# RL6678_IP_SVD register map
Vendor: Realtek
Registers are 32-bit, read-write, reset 0x0 unless marked. A register's access mark holds for its fields unless they carry their own. Offsets are from the block's base; [hi:lo] are bit positions; lines under a group give offsets from that group; {n}, {i} and the like mark numbered series; <NAME> marks a mode.

## DDRC_REG
Base 0x41100000
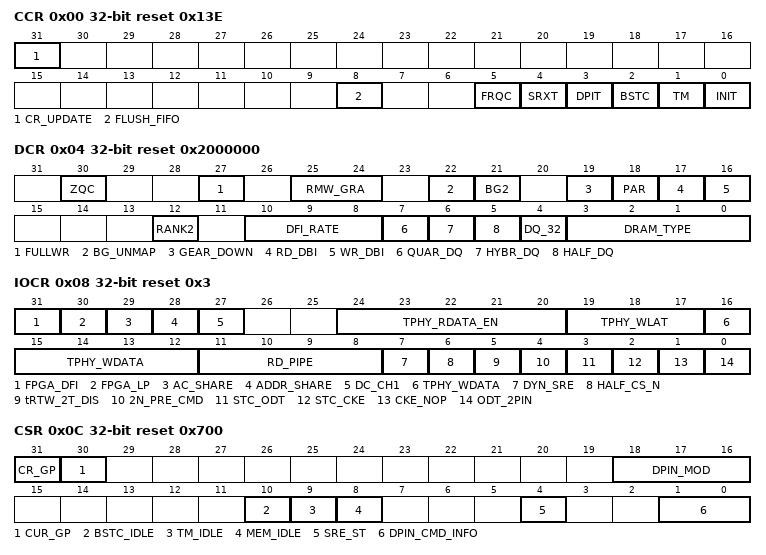
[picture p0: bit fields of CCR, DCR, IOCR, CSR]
0x00 CCR access per field reset 0x13E — Configuration Control Register
  [31] CR_UPDATE wo — To update the related control registers. Control registers: DCR, IOCR, CSR, MR_INFO,and MRx.To update the registers dynamically, it only allows until all transitions are complete. Timing counter registers: TPR0, TPR1, TPR2, and TPR3.
  [8] FLUSH_FIFO rw — Flush all FIFO in DRAMC. Write: 0: Not to flush FIFO 1: Start to Flush FIFO Read: 0: It is still active to flush FIFO. 1: Flushing FIFO operation is done.
  [5] FRQC rw — Set to implementation FRQC function. DRAMC would be automatically to implement serial operations and cooperate with RTK_PHY at the next Auto-refresh implementation finish. The operations include Self-refresh entry (SRE), to trigger RTK_PHY: Frequency change, wait until RTK_PHY: Frequency change done, set DRAM exit Self refresh mode (SRX) and re-initialize DRAM to set mode registers. The corresponding register group is according to CR_CSR.GP. Write: 0: Not to implement FRQC function. 1: Set FRQC function Read : 0: FRQC_function is still active. 1: FRQC function done. *Only support with configuration: FRQC_SUPPORT.
  [4] SRXT rw — Set to implementation SREX function. DRAMC would be automatically to implement DRAM: Self- Refresh entry command (SRE) at the next Auto-Refresh implementation finishing. And DRAMC would issue DRAM: Self-Refresh exit command (SRX) if Read/Write data access to DRAM. CR_CSR.SRE_ST is indicated DRAMC still implement SRE function. Write: 0: Not to set AUTO_SREX function. 1: Set AUTO_SREX function Read : 0: AUTO_SREX function is still active. 1: Indicates AUTO_SREX function done (SREX_DONE).
  [3] DPIT rw — Start to implement DPIN function. According to CR_CMD_DPIN//CR_CMD_DPIN_NDGE/CR_TIE_DPIN register value to set to DRAM pins. Write: 0: Not to set value to DRAM command pins. 1: Set value to DRAM pins. Read: 0: DPIN function is still active. 1: Indicates that DRAM command had issued to DRAM (DPIN_DONE).
  [2] BSTC rw — Start to run BSTC function. Write: 0: Disable BSTC function 1: Run BSTC Function * Write enable only with BSTC module is configured. Read: 0: BSTC function is still active. 1: BSTC function is done (BSTC_DONE).
  [1] TM rw — Start to run TM function. Write: 0: Disable TM function 1: Run TM Function * Write enable only with CR_CSR.TM_IDLE=0 is configured. Read: 0: TM function is still active. 1: TM function is done.
  [0] INIT rw — Start to issue DRAM initialization sequence Write: 0: Disable DRAM initialization function 1: Enable DRAM initialization function Read: 0: DRAM initialization function is still active 1: DRAM initialization function is done (INIT_DONE).
0x04 DCR reset 0x2000000 — DRAM Configuration Control Register
  [30] ZQC — Issue DRAM ZQCS/ZQCL command after serial Auto-refresh command implementation. This function should set with CR_DRR.ZQCL_INV and CR_TPR2.ZQCS_INV. Note: LPDDR4 does not support ZQCx command.
  [27] FULLWR — Always Full Write hint to RXI316. RXI316 will recognize RMW when transaction is not aligned to dram atomic size or it's partial write. * Only available (can write, and be meaningful) when ECC_EN (/FULLWR_EN/DHC_STARK_EN) is defined.
  [25:24] RMW_GRA — RMW granularity to RXI316. 2'b00: 16-bit 2'b01: 32-bit 2'b10: 64-bit 2'b11: 128-bit * Only available when ECC_EN (/SEC_EN/FULLWR_EN/DHC_STARK_EN) is defined.
  [22] BG_UNMAP — Disable to remap BG0 function to optimize DDR4:tCCD_L. CMD to CMD can be continuously in DDR4: burst access at BG remap function. BG remap function would cause DRAM active banks only 1/2 Bank number. For example, BANK0 and BANK4 would active with the same ROW address. 0: Enable BG0 remap 1: Disable BG0 remap * Only available (can write, and be meaningful) when DDR4_DRAM is defined.
  [21] BG2 — Support BankGroup2 function for DDR4. *Only support with configuration: BG BITS = 2.
  [19] GEAR_DOWN — Sets GEAR_DOWN function for DDR4 DRAM command and xDQ pins would be operated valid at 2 cycles. Before to implement this function, DRAM should set into Gear Down mode.
  [18] PAR — Sets PAR function for DDR4 DRAM priority pin would execute with the related pins. Before to implement this function, DRAM should enable CA parity mode.
  [17] RD_DBI — Sets READ DBI function for DDR4/LPDDR4 If setting this function, DRAMC would invert DRAM read data if DM_n/DM is indicate to DBI. Before to implement this function, DRAM should set to enable Read DBI and Read latency should be added according to DRAM spec.
  [16] WR_DBI — Sets Write DBI function for LPDDR4 (DDR4: WR_DBI only can be implemented at BSTC: WR without mask write). If setting this function, DRAMC would set DBI function at write data and write mask bits. Before to implement this function, DRAM should set to enable Write DBI.
  [12] RANK2 — Set DRAM RANK2 architecture implement. In RANK2 architecture, it should have 2 CS pins and Command/DQ bus is shared to connect with 2 DRAM dies. CR_TPR3.tCCD_R should be set for this function. *Only support with configuration: RANK_BITS = 2
  [10:8] DFI_RATE — Sets DFI ratio. 3'b001: 1:1 3'b010: 2:1 Others: Reserved *If using SDR, it doesn't support DFI
  [7] QUAR_DQ — Setting the DDR architecture is Half of DQ_32. If setting QUAR_DQ, CR_DCR.{HYBR_DQ, HALF_DQ, DQ_DQ32} should set 0. *Only support with configuration: QUAR_DQ_EN.
  [6] HYBR_DQ — Indicates DRAM architecture is (Big+ Little) density. To access DRAM in DQx16-bit or DQx32-bit is according to CR_MISC.HYBR_SIZE. If setting HYBR_DQ, CR_DCR.{HALF_DQ, DQ32} should set 0. *Only support with configuration: HYBR_DQ.
  [5] HALF_DQ — Setting the DDR architecture is Half of DQ_32. If setting HALF_DQ, CR_DCR.{QUAR_DQ, HYBR_DQ, DQ_DQ32} should set 0.
  [4] DQ_32 — Sets the DDR architecture is 2 x 16-Bit DRAM. It is valid to set if the hardware architecture is valid configuration. If setting DQ_32, CR_DCR.{HYBR_DQ, HALF_DQ32} should be set to 0.
  [3:0] DRAM_TYPE — Indicates the target DRAM type 4'b0001: DDR1 4'b0010: DDR2 4'b0011: DDR3 4'b0100: DDR4 4'b1001: LPDDR1 4'b1010: LPDDR2 4'b1011: LPDDR3 4'b1100: LPDDR4 Others: reserved
0x08 IOCR reset 0x3 — I/O Configuration Control Register
  [31] FPGA_DFI — Enable to connect external PHY on FPGA
  [30] FPGA_LP — Enable to loopback mode form output DFI ports to input DFI ports on FPGA.
  [29] AC_SHARE — Enable to share DFI interface: command and address with CH1: DRAMC. Ch0: DFI interface is only used DFI phase 0 (xxx_p0) Ch1: DFI interface is only used DFI phase 1 (xxx_p1) If enable this function, DRAM command is only to support 1T mode.
  [28] ADDR_SHARE — Enable to share DFI interface: address with CH1: DRAMC for LPDDR4
  [27] DC_CH1 — Enable CH1: DRAMC clock for AC_SHARE, ADDR_SHARE or Dual Channel function.
  [24:20] TPHY_RDATA_EN — Sets the delay latency from DFI read command to dfi_rddata_en signal. If it works on DDR, the smallest value is 1.
  [19:17] TPHY_WLAT — Sets the delay latency from DFI write command to dfi_wrdata_en signal. If it works on DDR type, the smallest value is 0.
  [16:12] TPHY_WDATA — Sets the delay latency from dfi_wrdata_en signal to dfi_wddata. If it works on DDR type, the smallest value is 1.
  [11:8] RD_PIPE — Sets the extra delay latency of CAS on SDR. If it works on SDR, the smallest value is 0.
  [7] DYN_SRE — Set DRAMC: dynamic self refresh. According to CR_DPERF0.DIW value, DRAMC will issue SREF automatically.
  [6] HALF_CS_N — Sets DRAM:CS only keeps half cycle for LPDDR2/3.
  [5] tRTW_2T_DIS — Sets DRAM: read -> write command interval time >= 2t.
  [4] 2N_PRE_CMD — Sets DRAM: command pins = keeps 2t* but DRAM:CS keeps only 1t*. If DFI ratio is1, it only can be allowed setting to 0. If DFI ratio is 2, it would suggest setting to 1. The timing margin is better at DRAM. In LPDDR4, it doesn't support.
  [3] STC_ODT — Set DRAM: ODT value is static according to CR_TIE_DPIN.ODT. Else DRAMC supports dynamic ODT function.
  [2] STC_CKE — Set DRAM: CKE value is static according to CR_TIE_DPIN.CKE. Else DRAMC supports dynamic CKE function.
  [1] CKE_NOP — Set before to implement DPIT function with CR_TIE_DPIN.CKE is 0 (Low power entry command) with 2 NOP CMD for LPDDR3. 0: No NOP CMD after low power entry 1: Follow with 2 NOP CMD for low power entry
  [0] ODT_2PIN — Driver the same value to all ODT pins according to CR_TIE_DPIN.ODT. *Only support with configuration: ODT_BITS=2.
0x0C CSR access per field reset 0x700 — Controller Status Register
  [31] CR_GP rw — Set to indicate control register group number.ForFRQC function, there are 2 group registers at GP0/GP1: (CR_IOCR, CR_DRR, CR_TPR0~3, and CR_MRx). Before setting the particular group number registers,usershould set this field to decide which group number is used to read/write. Anddifferent group numberof CR_IOCR, CR_DRR, CR_TPR0~3, and CR_MRx aresharethe same address mapping. *CR_GP:1 only supports with configuration: FRQC_SUPPORT.
  [30] CUR_GP ro — Indicates the current group number which is internal used. CUR _GP is updated when FRQC is trigger and FRQC function is done.
  [18:16] DPIN_MOD rw — Indicate DPIN function: DRAM command type before DPIT implementation. Used to sync DRAMC: internal each bank page information. 3'b000: DRAM command, without data 3'b001: DRAM: MRR, used for LPDDR234 3'b010: DRAM: Read data 3'b011: DRAM: Write data 3'b100: DRAM: MPC Write, only used for LPDDR4 3'b101: DRAM: MPC Read, only used for LPDDR4 Others are reserved
  [10] BSTC_IDLE rw — Disable BSTC function state Write: To set BSTC idle state 0: Enable BSTC function 1: Set BSTC idle state; disable BSTC function. Read: To check if BSTC state is in idle 0: BSTC function implementationis allowed. 1: BSTC state is idle and user can't implement BSTC function.
  [9] TM_IDLE rw — Disable TM function state Write: To set TM idle state 0: Enable TM function 1: Set TM idle state; disable TM function. Read: To check if TM state is in idle 0: TM function implementations allowed. 1: TM state is idle and user can't implement TM function.
  [8] MEM_IDLE rw — Disable memory access state Write: To set memory access idle state 0: Enable memory access state. 1: Set memory access idle; disable memory access. Read: To check ifmemory access stateis in idle 0: Access DRAM is allowed. 1: Memory state is idle and user can't access DRAM throughdata bus.
  [4] SRE_ST ro — Indicates DRAMC is issuing SRE command to DRAM.
  [1:0] DPIN_CMD_INFO rw — Set DRAM command with data type before DPIT implementation. 2'b00: Reserved 2'b01: DPIN precharge all 2'b10: DPIN precharge 2'b11: DPIN active
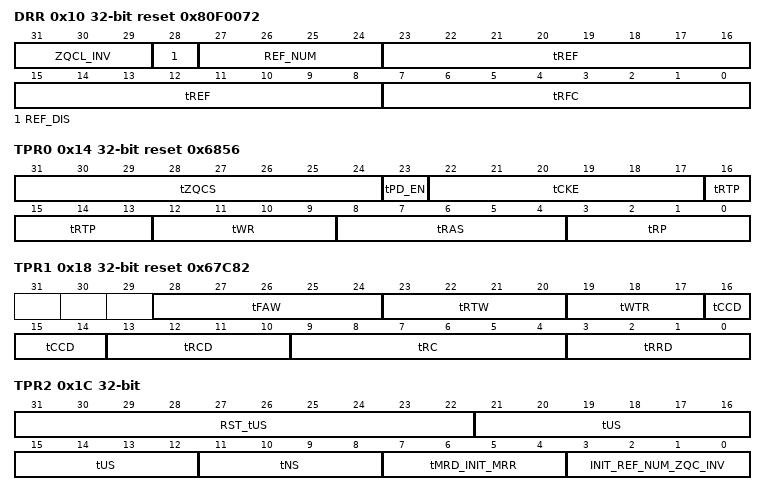
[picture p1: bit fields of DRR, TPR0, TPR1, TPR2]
0x10 DRR reset 0x80F0072 — DRAM Refresh Control Register
  [31:29] ZQCL_INV — It is used for indicate ZQCL implementation interval time after ZQCS implementation times. For example: set ZQC_INV to 2 and ZQCL to1 -----|||||------|||||+ZQCS -----|||||------|||||+ZQCL---- Serial-REF Serial-REF+ZQCS Serial-REF Serial-REF+ZQCL *LPDDR4 does not support ZQCx command.
  [28] REF_DIS — Disable DRAMC issues Refresh command to DRAM.
  [27:24] REF_NUM — Sets the number of Refresh commands to issue in between two surrounding Refresh commands
  [23:8] tREF — Maximum average Refresh commands delay cycles. CR_tREF[4:0] is also used to indicate the early cycles to inform RTK_PHY before ZQC command implementation.
  [7:0] tRFC — Refresh to Active or Refresh commands delay cycles. Total tRFC= {CR_TPR3.tRFC_MSB, CR_DRR[7:0].tRTW}
0x14 TPR0 reset 0x6856 — DRAM Timing Parameter Register 0
  [31:24] tZQCS — ZQCS command cycles
  [23] tPD_EN — Enable to keep CKE is registered 0 before CKE is registered to 1 for Precharge/Active power down. The timing is equal to CR_TPR0.tCKE. *Some DRAM spec defines thetimingtotCKE/tXP. *Not used this function in SDR/DDR1.
  [22:17] tCKE — Enable to keep CKE is registered 1 before the next valid command for Precharge/Active power down exit. The timing = Max(tCKE,tXP) cycles For AUTO_SREX function, tCKE= {CR_TPR2.tNS, CR_TPR0.tCKE} else tCKE = {CR_TPR0.tCKE}
  [16:13] tRTP — Read to Precharge command delay cycles for Percharge command. The tRTP should be followed as Equation/DFI_RATIO. SDR: BL/2 DDR1: BL/2 DDR2: AL + BL/2 - 2 +tRTP DDR3/4: AL+tRTP LPDDR1: BL/2 LPDDR2: BL/2 - 1(S2)/2(S4) +tRTP LPDDR3: BL/2 - 4 +tRTP LPDDR4: BL/2 - 8 +tRTP BL: DRAM burst length
  [12:9] tWR — Write recovery delay cycles for Precharge command. Totalt WR= {CR_TPR3.tWR_MSB, CR_TPR0[12:9].tWR}
  [8:4] tRAS — Active to Precharge command delay cycles totalt RAS= {CR_TPR3.tRAS_MSB, CR_TPR0[8:4].tRAS}
  [3:0] tRP — Precharge command cycles. tRP is also indicated to LPDDR234: tRPpb for signal perbank precharge time.
0x18 TPR1 reset 0x67C82 — DRAM Timing Parameter Register 1
  [28:24] tFAW — Four active window cycles total tFAW={CR_TPR3.tFAW_MSB, CR_TPR1[28:24].tFAW}
  [23:20] tRTW — Read to Write command delay cycles. The equation of tRTW: totalt RTW= {CR_TPR3.tRTW_MSB, CR_TPR1[23:20].tRTW} * Minimum value is 0. tRTW: SDR: BL+RL DDR1: BL/2+RL DDR2: BL/2 + 2 DDR3/4: RL + BL/2 + 2 - WL LPDDR1: BL/2 + RL LPDDR2: RL + RU(tDQSCKmax) + BL/2 + 1 -WL LPDDR3: RL + RU(tDQSCKmax) + BL/2 + 1 -WL LPDDR4: RL+RU(tDQSCKmax/tCK)+BL/2 - WL + RD(tRPST) + tWPRE * LPDDR4: Read parity latency should be added into RL.
  [19:17] tWTR — Write to Read command delay cycles In DDR4 tWTR_L = CR_TPR1.tWTR for the same Bank Group. The equation of tWTR: totaltWTR= {CR_TPR3.tWTR_MSB, CR_TPR1[19:17].tWTR} *Minima value is 0.
  [16:14] tCCD — CAS to CAS command delay cycles. CR_tPR1.tCCD = (tCCD/ DFI_RATIO) In LPDDR4,tCCDMW= CR_TPR1.tCCD * 2^2 cycles. In DDR4 tRRD_L = CR_TPR1.tCCD for the same Bank Group.
  [13:10] tRCD — Active to Read or Write delay cycles
  [9:4] tRC — Active to Active or Refresh command delay cycles for the same Bank.
  [3:0] tRRD — Active to Active command delay cycles for the different Bank. In DDR4 tRRD_L = CR_TPR1.tRRD for the same Bank Group.
0x1C TPR2 — DRAM Timing Parameter Register 2
  [31:22] RST_tUS — Set to keep Reset low at least times and it must be >1. The time=CR_TPR2.RST_tUS*210 < 220 cycles For DDR3, it is least to wait 200us For DDR4, it is least to wait 100ns For LPDDR2/3:tINIT5, it is least to wait 10us The time = CR_TPR2.tUS *211 < 221 cycles For LPDDR4:tINIT1, it is least to wait 200us *Other DRAM types don't used. *CR_TPR2.RST_tUS can't be 0 and can't equal to CR_TPR2.tUS. *Only support without configuration: CR_INTI_RMBIT
  [21:12] tUS — Set to wait CKE stable at least tUS ns. The time=CR_TPR2.tUS*210 < 220 cycles For SDR, it is least to wait 100us. For DDR1/2, it is least to wait 200us. For DDR3/4, it is least to wait 500us ForLPDDR1~3: tINIT3, it is least to wait 200us The time=CR_TPR2.tUS*211 < 221 cycles. For LPDDR4:tINIT3, it is least to wait 2ms. *CR_TPR2.tUS can't be0 can't equal to CR_TPR2.RST_tUS. *Only support without configuration: CR_INTI_RMBIT.
  [11:8] tNS — Set to wait at least tNS ns. The time=CR_TPR2.tNS*27 cycles For SDR/DDR1/LPDDR1, it is least to wait 1tCK For DDR2, it is least to wait 400ns For DDR3/4, it is least to wait max (5tck, ~tRFC+10ns). For LPDDR2/3:tINIT1, itis least towait 100 ns The time >=CR_TPR2.tNS*28 cycles For LPDDR4:tINIT4, it is least to wait 2us AfterINIT_DONE,this is used the extend bits of CR_TPR0.tCKE for AUTO_SREX function. *CR_TPR2.tNS can't be 0. *If CR_TPR2.tNS[3] ==1, CR_TPR2.tNS[2:0] should be >= 1. *Only support without configuration: CR_INTI_RMBIT
  [7:4] tMRD_INIT_MRR — Mode register operations delay cycles. The value =max (tMRD, tMOD) 2: CR_TPR2[4].INIT_MRR (CR_TPR2.tMRD[0]): is also use to enable MRR checking mode status at LPDDR2/LPDDR3: initialization flow to save tINIT5 timing (~10 us). 3: When using lpddr4, needs to share this field [6:4] with timing CR_tescke of SRE function.
  [3:0] INIT_REF_NUM_ZQC_INV — Set the number of Refresh command to issue in DRAM (SDR/DDR1/DDR2) initialization flow. After DRAM initial flow, it isalsoused forindicate ZQCS implementation interval times after serial AUTO_Refresh implementation times. For example: set ZQC_INV to 2 and ZQCL to1 -----||||| -------|||||+ZQCS -------|||||--------|||||+ZQCL---- Serial-REF Serial-REF+ZQCS Serial-REF Serial-REF+ZQCL
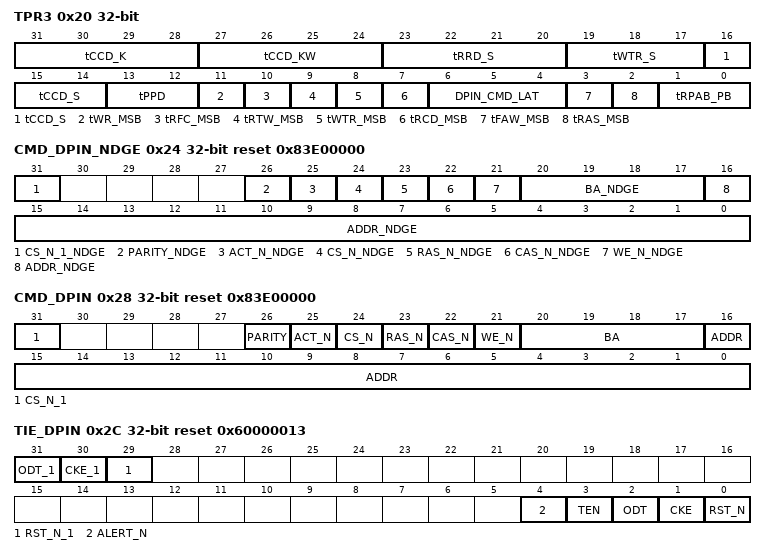
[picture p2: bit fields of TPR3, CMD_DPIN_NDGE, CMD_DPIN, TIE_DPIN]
0x20 TPR3 — DRAM Timing Parameter Register 3
  [31:28] tCCD_K — CAS to CAS command extra delay cycles for different rank DRAM die. The different rank CAS->CAS latency = CR_TPR1.tCCD + CR_TPR1.tCCD_K
  [27:24] tCCD_KW — WR to WR command extra delay cycles for different rank DRAM die. The different rank WR->WR latency = CR_TPR1.tCCD + CR_TPR1.tCCD_KW
  [23:20] tRRD_S — Active to Active command delay cycles for the different bank group in DDR4. *CR_TPR1.tRRD is used for the same bank group in DDR4:tRRD_L
  [19:17] tWTR_S — Delay cycles start of internal Write transaction to internal read command at different bank group in DDR4. *CR_TPR1.tWTR is used to the same bank group in DDR4.tWTR_L
  [16:14] tCCD_S — CAS to CAS command delay cycles at different bank group in DDR4. *CR_TPR1.tCCD is used to the same bank group in DDR4.tCCD_L
  [13:12] tPPD — Different bank Precharge to Precharge command delay cycles for LPDDR4
  [11] tWR_MSB — Extend MSB of tWR cycles, total tWR = {CR_TPR3.tWR_MSB, CR_TP R0[12:9].tWR}
  [10] tRFC_MSB — Extend MSB oftRFC cycles, total tRFC = {CR_TPR3.tRFC_MSB, CR_DRR[7:0].tRTW}
  [9] tRTW_MSB — Extend MSBoftRTW cycles, total tRTW = {CR_TPR3.tRTW_MSB, CR_TPR1[23:20].tRTW}
  [8] tWTR_MSB — Extend MSBoftWTR cycles, total tWTR = {CR_TPR3.tWTR_MSB, CR_TPR1[19:17].tWTR}
  [7] tRCD_MSB — Extend MSBoftWTR cycles, total tRCD = {CR_TPR3.tRCD_MSB, CR_TPR1[13:10].tRCD}
  [6:4] DPIN_CMD_LAT — Set CS_N pin delay cycles with others command pins. *It is usually CS_N to avoid setup/hold violation for DDR4 gear down function.
  [3] tFAW_MSB — Extend MSBoftFAW cycles. total tFAW = { CR_TPR3.tFAW_MSB, CR_TPR1[28:24].tFAW}
  [2] tRAS_MSB — Extend MSBoftRAS cycles. total tRAS = {CR_TPR3.tRAS_MSB, CR_TPR0[8:4].tRAS}
  [1:0] tRPAB_PB — Precharge all command- precharge command cycles tRPAB_PB=tRPab - tRPpb For LPDDR2/3/4, tRPab would different with tRPpb
0x24 CMD_DPIN_NDGE reset 0x83E00000 — Command Data Pin Register for LPDDR2/3
  [31] CS_N_1_NDGE — Set the value of CS_1 pin if parameter: CS_BITS=2
  [26] PARITY_NDGE — Set the value of PARITY pin for DDR4
  [25] ACT_N_NDGE — Set the value of ACT_N pin for DDR4
  [24] CS_N_NDGE — Set the value of CS_N pin
  [23] RAS_N_NDGE — Set the value of RAS_N pin
  [22] CAS_N_NDGE — Set the value of CAS_N pin
  [21] WE_N_NDGE — Set the value of WE_N pin
  [20:17] BA_NDGE — Set the value of BA pins
  [16:0] ADDR_NDGE — Set the value of ADDR pins DRAM Active command: this is row address DRAM Write/Read command: this is column address
0x28 CMD_DPIN reset 0x83E00000 — Command Data Pin Register
  [31] CS_N_1 — Set the value of CS_1 pin if parameter: CS_BITS=2
  [26] PARITY — Set the value of PARITY pin for DDR4
  [25] ACT_N — Set the value of ACT_N pin for DDR4
  [24] CS_N — Set the value of CS_N pin
  [23] RAS_N — Set the value of RAS_N pin
  [22] CAS_N — Set the value of CAS_N pin
  [21] WE_N — Set the value of WE_N pin
  [20:17] BA — Set the value of BA pins
  [16:0] ADDR — Set the value of ADDR pins DRAM Active command: this is row address DRAM Write/Read command: this is column address
0x2C TIE_DPIN reset 0x60000013 — Tied Data Pin Register
  [31] ODT_1 — Set the value of ODT_1 pin if parameter: ODT_BITS>1. If CR_DCR.STD_ODT setting, ODT_1 pin valuewould be set directly and immediately according to this field.
  [30] CKE_1 — Set the value of CKE_1 pin directly and immediatelyaccording to this field if parameter CKE_BITS=2. If CR_DCR.STD_CKE setting, CKE_1 pin value would be according to this field and setting by DPIT function
  [29] RST_N_1 — Set the value of RST_N_1 pin directly and immediately according to this field if parameter RST_BITS=2.
  [4] ALERT_N — Set the value of ALERT_N pin. * Only available when enable DDR4_EN
  [3] TEN — Set the value of TEN pin. * Only available when enable DDR4_EN
  [2] ODT — Set the value of ODT pin. If CR_DCR.STD_ODTsetting, ODTpin valuewould be set directly and immediately according to this field.
  [1] CKE — Set the value of CKE pin. If CR_DCR.STD_CKE setting, CKE pin value would be according to this field and setting by DPIT function.
  [0] RST_N — Set the value of RST_N pin directly and immediately according to this field.
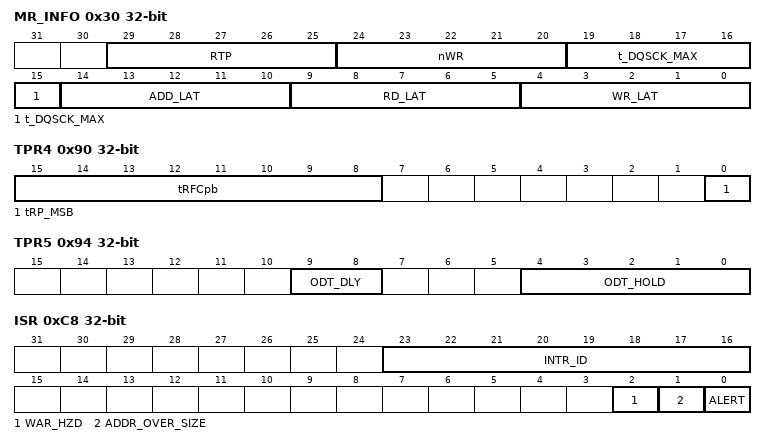
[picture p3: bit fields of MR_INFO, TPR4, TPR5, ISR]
0x30 MR_INFO — Mode Latency Information Register
  [29:25] RTP — It is DRAM mode register: write recoverary cyclesvaluefor AutoPrecharge command. It dependes on DRAM mode register definition. The equation is DRAM RTP value/(DFI_RATIO * DRAM_PERIOD)
  [24:20] nWR — It is DRAM mode register: write recoverary cyclesvaluefor AutoPrecharge command. It dependes on DRAM moderegister definition. The equation is: DRAM write recovery value/(DFI_RATIO * DRAM_PERIOD)
  [19:15] t_DQSCK_MAX — Indicates tDQSCK_MAX cycle value for LPDDR23 The equation is (tDQSCK_MAX/ DFI_RATIO * DRAM_PERIOD)
  [14:10] ADD_LAT — Indicates DRAM additive latency.
  [9:5] RD_LAT — Indicates DRAM read data latency. The equation is (Read latency + Additive latency +*Parity latency(DDR4))/DFI_RATIO
  [4:0] WR_LAT — Indicates DRAM write data latency. The equation is (Write latency+ Additive latency +*Parity latency(DDR4))/DFI_RATIO
0x34 MR0 reset 0xAA2 — DRAM Mode Register 0
  [16:0] MR0 — Sets the value to Mode register MR0 in DRAM initialization flow (INIT function).
{0x34+4i} MR{i} (i=1..3) — DRAM Mode Register {i}
  [16:0] MR{i} — Sets the value to Mode register MR{i} in DRAM initialization flow (INIT function).
0x44 MR4 — DRAM Mode Register 4
  [16:0] MR4 — Sets the value to Mode register MR4 in DDR4 initialization flow (INIT function).
0x48 MR5 reset 0x400 — DRAM Mode Register 5
  [16:0] MR5 — Sets the value to Mode register MR5 in DDR4 initialization flow (INIT function).
0x4C MR6 — DRAM Mode Register 6
  [16:0] MR6 — Sets the value to Mode register MR6 in DDR4 initialization flow (INIT function).
0x50 MR11 — DRAM Mode Register 11
  [16:0] MR11 — Sets the value to Mode register MR11 in LPDDR4 initialization flow (INIT function).
0x54 MR12 — DRAM Mode Register 12
  [16:0] MR12 — Sets the value to Mode register MR12 in LPDDR4 initialization flow (INIT function).
0x58 MR13 — DRAM Mode Register 13
  [16:0] MR13 — Sets the value to Mode register MR13 in LPDDR4initialization flow (INIT function). MR13 is special used to set for LPDDR4: Frequency Set Point function to refer INIT function.
0x5C MR14 — DRAM Mode Register 14
  [16:0] MR14 — Sets the value to Mode register MR14 in LPDDR4 initialization flow (INIT function).
0x60 MR22 — DRAM Mode Register 22
  [16:0] MR22 — Sets the value to Mode register MR22 in LPDDR4 initialization flow (INIT function).
0x90 TPR4 — DRAM Timing Parameter Register 4
  [15:8] tRFCpb — Sets the value to REFpb to next valid command extra delay cycles for refresh per bank function Only lpddr2, lpddr3, lpddr4 support REFpb commaned If setting CR_tRFCpb=0, it won't enable refpb function
  [0] tRP_MSB — Extend MSB of tRP cycles. total tRP = {CR_TPR4.tRP_MSB, CR_TPR0[3:0].tRP}
0x94 TPR5 — DRAM Timing Parameter Register 5
  [9:8] ODT_DLY — Sets ODT on delay time when DRAM command is Write operation. Time unit: DRAM cycles Suggestion: 0
  [4:0] ODT_HOLD — To keep ODT on time after ODT delay time. Time unit: DRAM cycles Suggestion: DDR2: (WL+ DRAM burst length /2 + 1) DDR3/4: (DRAM burst length /2 + 2) LPDDR3: (WL+ DRAM burst length /2 + 1)
0xC0 DPDRI — In DPIN data flow, set value of DPDR index
  [6:0] DPDRI — It is used to set the value of DPDR index in DPIN data flow. Index 0~ 31: DPIN read data Index 32~ 63: DPIN write data Index 64~ 67: DPIN write data mask Index 68: DPIN read data level(word, read only) Index 69: DPIN write data level(word, read only)
0xC4 DPDR — In DPIN data flow, setvalueaccording to DPDRI
  [31:0] DPDR — It is used to write/read data according to CR_DPDRI. Write: the data of CR_DPDR would write into CR_DPDRI index address. Read: the data of CR_DPDR would read from CR_DPDRI index address.
0xC8 ISR — Controller Interrupt Register
  [23:16] INTR_ID — Interrupt ID Number, include Assertion Group and Assertion Number {Assertion Group, Assertion Number}. Bit[23:22] indicates Assertion Group. Bit[21:16] indicates Assertion Number.
  [2] WAR_HZD — Write after read (war) hazard interrupt.
  [1] ADDR_OVER_SIZE — This field is working when not define ERR_HANDLER_EN If not define ERR_HANDLER_EN, Command address exceeds maximum DRAM size (CR_DRAM_SIZE) interrupt. If define ERR_HANDLER_EN, this interrupt would not active.
  [0] ALERT — DDR4 alert interrupt.
0xCC IMR reset 0xFFFF — DRAMC interrupt mask bits
  [15:0] INTR_MASK — CR_ISR [15:0] interrupt bit mask. 0: Interrupt bit is masked. 1: Interrupt bit enable.
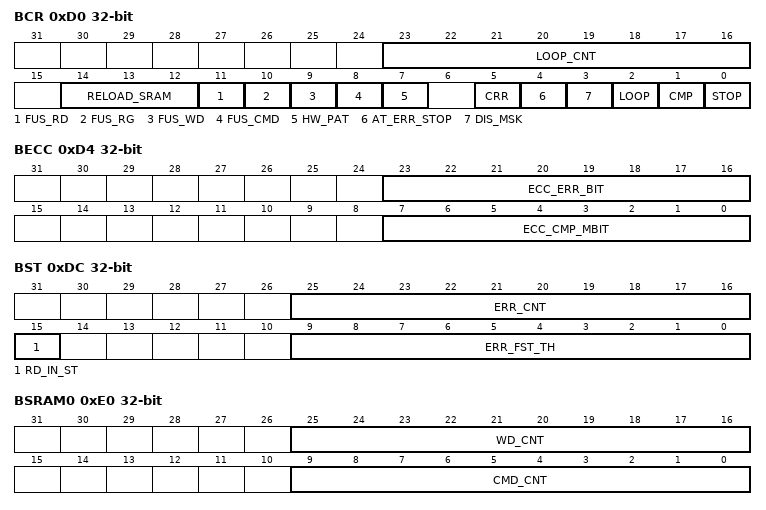
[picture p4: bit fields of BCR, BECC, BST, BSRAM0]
0xD0 BCR access per field — BSTC Control Register
  [23:16] LOOP_CNT rw — If set LOOP_CNT >0 and enable CR_BCR.LOOP, BSTC test patterns would be tested in LOOP_CNT times.
  [14:12] RELOAD_SRAM rw — RELOAD_SRAM[2]: Reload to keep the previous RG_SRAM level RELOAD_SRAM[1]: Reload to keep the previous WD_SRAM level RELOAD_SRAM[0]: Reload to keep the previous CMD_SRAM level
  [11] FUS_RD rw — Flush RD_SRAM data.
  [10] FUS_RG rw — Flush RG_SRAM data.
  [9] FUS_WD rw — Flush WD_SRAM data.
  [8] FUS_CMD rw — Flush CMD_SRAM data.
  [7] HW_PAT rw — Indicates WD/RG patterns are generated by hardware design. Before BSTC function implementation user must set this field and BST.WD_EX_CNT then write a dummy data to WD_SRAM to load the expected number to internal WD counter. If Write data is from inWR_SRAM, internal WD counter is updated by WR_SRAM writing.
  [5] CRR wo — Sets to clean CR_BER and CR_BST.{ERR_CNT, ERR_FST_TH} registers
  [4] AT_ERR_STOP rw — DRAMC would stop the BSTC function implementation if RD_SRAM and RG_SRAM compare error data automatically. To enable this function it also must enable the loop mode and compare mode (CR_BCR[2:1]).
  [3] DIS_MSK rw — Disables using MSK_SRAM. DRAMC would write full data to DRAM without masking function.
  [2] LOOP rw — Enables loop mode. DRAMC repeats to implement BSTC function for overnight testing
  [1] CMP rw — Enables compare mode. DRAMC would compare read data form DRAM with the expected data in RG_SRAM.
  [0] STOP wo — Disables to run BSTC hardware function. This bit read data is reserved to 0.
0xD4 BECC access per field — BSTC Sideband ECC Register
  [23:16] ECC_ERR_BIT ro — Indicates which bit ever had occurred error in auto compare function. It can clear by CR_BCR.CRR. *When using sideband ecc function, it will needs additional DQ8 width. If ECC_EN configuration is not set, this field are no used.
  [7:0] ECC_CMP_MBIT rw — It is used to mask data bit to compare in auto compare function. *When using sideband ecc function, it will needs additional DQ8 width. If ECC_EN configuration is not set, this field aren't valid to set.
0xD8 BCM — BSTC compare bit mask Register
  [31:0] BCM_CMP_MBIT — It is used to mask data bit to compare in auto compare function. *If DQ32 configuration is not set, it is only 16 bit valid to set.
0xDC BST ro — BSTC Status Register
  [25:16] ERR_CNT — Indicates the entry number of the error read data if compare mode is setting. It can clear by CR_BCR.CRR. For example: if all return data are error BUS_64, DRAM BST8, DRAM x16, 2x DRAM Read command ERR_CNT max value=2x (8x16)/64 = 4 BUS_128, DRAM BST8, DRAM x16 ERR_CNT max value=2x(8x16)/128 = 2 BUS_128, DRAM BST8, DRAM x32 ERR_CNT max value=2x(8x32)/128 = 4
  [15] RD_IN_ST — Indicates DRAMC had received read data from DRAM. It can clear by BSTC_START function.
  [9:0] ERR_FST_TH — Indicates the address of the first error data in the RD_SRAM. It can clear by CR_BCR.CRR.
0xE0 BSRAM0 ro — BSTC SRAM Status Register 0
  [25:16] WD_CNT — Indicates the word counts of the data in the write data SRAM (WD_SRAM) For example: There is one valid entry at WD_SRAM. If DATA BUS Width is 64-bit, WD_CNT is 2 If DATA BUS Width is 128-bit, WD_CNT is 4
  [9:0] CMD_CNT — Indicates the word counts of the data in the command SRAM (CMD_SRAM) For example, there is one valid entry at CMD_SRAM (CMD_SRAM bit width is 37) CMD_CNT = CMD_SRAM bit width/32 = 2
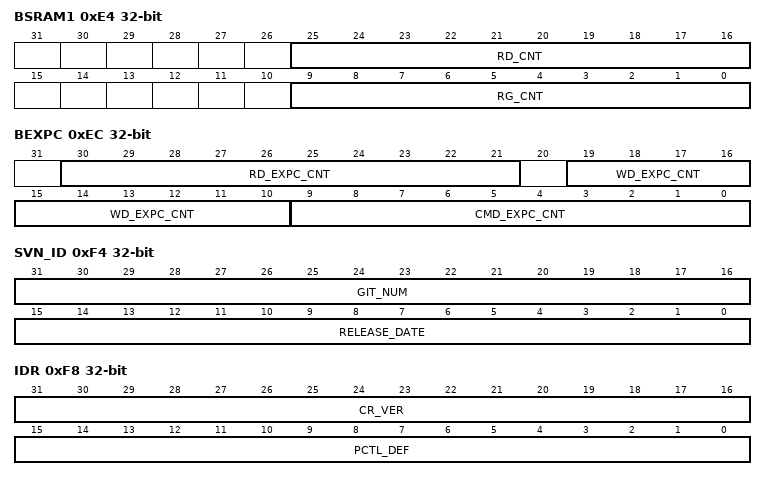
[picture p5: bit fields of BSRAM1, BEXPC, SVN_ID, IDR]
0xE4 BSRAM1 ro — BSTC SRAM Status Register 1
  [25:16] RD_CNT — Indicates the word counts of the data in the read data (RD_SRAM). For example: There is one valid entry at RD_SRAM. If DATA BUS Width is 64-bit, RD_CNT is 2 If DATA BUS Width is 128-bit, RD_CNT is 4
  [9:0] RG_CNT — Indicates the word counts of the data in the golden data SRAM (RG_SRAM) For example: There is one valid entry at RD_SRAM. If DATA BUS Width is 64-bit, RG_CNT is 2 If DATA BUS Width is 128-bit, RG_CNT is 4
0xE8 BER ro — BSTC Error Bit Register
  [31:0] ERR_BIT — Indicates which bit ever had occurred error in auto compare function. It can clear by CR_BCR.CRR. *If DQ32 configuration is not set,it is only 16 bit valid to set.
0xEC BEXPC — BSTC SRAM expected execute numbers of words register
  [30:21] RD_EXPC_CNT — Sets the expected word number of RD_SRAM. The equation is (total return bits) / 32. For example: 4 DRAM Read commands with DQ16, DRAM_BST8 RD_EXPC_CNT=(4x16x8)/32 = 16 4 DRAM Read commands with DQ32 & DRAM_BST8 RD_EXPC_CNT=(4x32x8)/32 =32
  [19:10] WD_EXPC_CNT — Sets the expected word number of WD_SRAM. The expected word number should equal all write command issue WD number. The equation is (total return bits) / 32. For example: Write commands with DQ16, DRAM_BST8 WD_EXPC_CNT=(4x16x8)/32 = 16 Write commands with DQ32 & DRAM_BST8 WD_EXPC_CNT=(4x32x8)/32 =32
  [9:0] CMD_EXPC_CNT — Sets the expected word number of CMD_SRAM. The equation is (total cmd bits) / 32. For example: 1 command for CMD_SRAM with 37 bits CMD_EXPC_CNT=(1x37)/32 = 2 1 command for CMD_SRAM with 31 bits CMD_EXPC_CNT=(1x31)/32 = 1
0xF4 SVN_ID ro — PCTL Version ID Register
  [31:16] GIT_NUM — Indicates the commit number of the released RTL code
  [15:0] RELEASE_DATE — Indicates the IP release date for the particular project
0xF8 IDR ro — PCTL Identification Register
  [31:16] CR_VER — The control register version number
  [15:0] PCTL_DEF — If user ties this field at input port tie, it indicates user definition. Or it only shows one main support DRAM type.
0xFC MSG — Reserved register
  [31:0] MSG — This is reversed register for DRAMC debug.
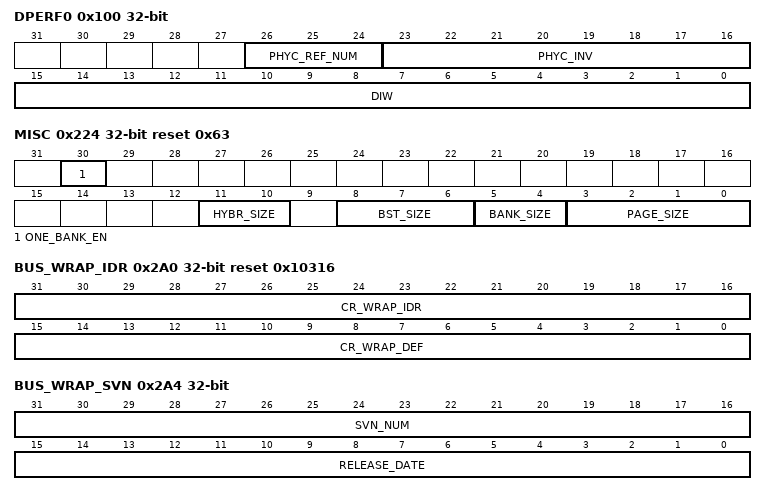
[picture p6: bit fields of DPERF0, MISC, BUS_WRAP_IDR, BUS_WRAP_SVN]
0x100 DPERF0 — DRAM Performance Regitser
  [26:24] PHYC_REF_NUM — Indicates an refab command number. After PHYC_INV interval, it needs to sending numbers of refab cmd for PHY calibration using. It is used for refpb function. It also needs to be used with PHYC_INV. If any value of PHYC_INV or PHYC_REF_NUM is 0, phy calibration function for refpb couldn't be enabled.
  [23:16] PHYC_INV — Indicates an interval. It needs to wait numbers of refpb cmd to DRAM, before start sending refab cmd for PHY calibration. It is used for refpb function. It also needs to be used with PHYC_REF_NUM. If any value of PHYC_INV or PHYC_REF_NUM is 0, phy calibration function for refpb couldn't be enabled.
  [15:0] DIW — Indicates cycles for a DRAM idle window. Means it has n cycles no any RD/WR cmd from bus and also have no command to send dram. If user has set this value, DRAMC is used to pull-in REF command, include REFab and REFpb cmd. If user has set this value and setting CR_IOCR.DYN_SRE, DRAMC will pull-in REF command and issue SREF command automatically.
0x224 MISC reset 0x63 — Memory Information Setting Control Register
  [30] ONE_BANK_EN — Indicates DRAM is only one bank and internal row address counter would be increasing if crossing page size.
  [11:10] HYBR_SIZE — Indicates the target DRAM page size (unit: Byte): 2'b000: 256M 2'b001: 512M 2'b010: 1G 2'b011: 2G According to CR_MISC. HYBR_SIZE to access DRAM in DQx16-bit or DQx32-bit. *It needs hardware configuration set HYBR_DRAM. For example: Setting HYBR_SIZE is 512MB, If bus_address >= 0x2000_0000, it only accesses DQx16-bit. If bus_address < 0x2000_0000, it would access DQx32-bit.
  [8:6] BST_SIZE — Indicates DRAMC to issue DRAM Burst size: 3'b000a4 3'b001: 8 3'010: 16 3'011: 2 and others are reserved.
  [5:4] BANK_SIZE — Indicates the target DRAM bank size*(CR_DCR.RANK2+1) 2'b00: 2 2'b01: 4 2'b10: 8 2'b11: 16
  [3:0] PAGE_SIZE — Indicates the target DRAM page size (unit: Byte) 4'b000: 256B 4'b001: 512B 4'b010: 1K 4'b011: 2K 4'b100: 4K 4'b101: 8K 4'b110: 16K 4'b101: 32K For example: If DRAM column address is 10-bit and DRAM bit number is x16, page size is equal to 210*16/8 => 2KB If DRAM column address is 10-bit and DRAM bit number is x32, page size is equal to 210*32/8 => 4KB
0x228 CHOP_SIZE reset 0x1 — ChopSize Control Register
  [2:0] CR_CHOP_SIZE — It determine the following items: chopsize to front-end.the space mapping between each entry of wcmd_buf and wdata_sram of wdata_buf.the bits of range when hazard check. Chop size (unit:byte): 3'd0: 8 3'd1: 16 3'd2: 32 3'd3: 64 3'd4: 128 *note 1: CR_CHOP_SIZE must be greater than or equal to dram_atomic_size. (dram_atomic_size= dram_dq_width * dram_burst_length) *note 2 : CR_CHOP_SIZE must be greater than or equal to data bus_width(DC_DATA_WIDTH) example: If DC_DATA_WIDTH=128-bit, CR_CHOP_SIZE=0 (8byte) is not available. *note 3: Max. value of CR_CHOP_SIZE depends on the config DC_MAX_CHOP_SIZE in config form. (e.g., If DC_MAX_CHOP_SIZE=32 (byte), CR_CHOP_SIZE can only set 0(8byte), 1(16byte), 2(32byte) )
0x230 DRAM_SIZE reset 0xFFFFFFFF — DRAM Size Control Register
  [31:0] DRAM_SIZE — DRAM max density, physical address range is 0 ~ dram_size. If master cmd address over dram_size, frontend will block this cmd not send to backend, and send ERROR response. Also frontend interrupt will asserted for this illegal access. DRAM total density, for example: 32Gb: 0xFFFF_FFFF 24Gb: 0xBFFF_FFFF (non-binary dram density ) 16Gb: 0x7FFF_FFFF 12Gb: 0x5FFF_FFFF (non-binary dram density ) 8Gb: 0x3FFF_FFFF 6Gb: 0x2FFF_FFFF (non-binary dram density ) 4Gb: 0x1FFF_FFFF 3Gb: 0x1EFF_FFFF (non-binary dram density ) 2Gb: 0x0FFF_FFFF
0x234 DSIZE_UP_4GB — DRAM Size Up 4GB Control Register
  [0] DSIZE_8GB — DRAM maximum access address, it is physical bus address. DRAM max size 8GB
0x2A0 BUS_WRAP_IDR ro reset 0x10316 — BUS_WRAP ID Number Control Register
  [31:16] CR_WRAP_IDR — Indicates BUS_WRAP ID number.
  [15:0] CR_WRAP_DEF — Indicates DRAMC number
0x2A4 BUS_WRAP_SVN ro — BUS_WRAP Version Control Register
  [31:16] SVN_NUM — Indicates the commit number of the release RTL code
  [15:0] RELEASE_DATE — Indicates the IP release date for the particular project
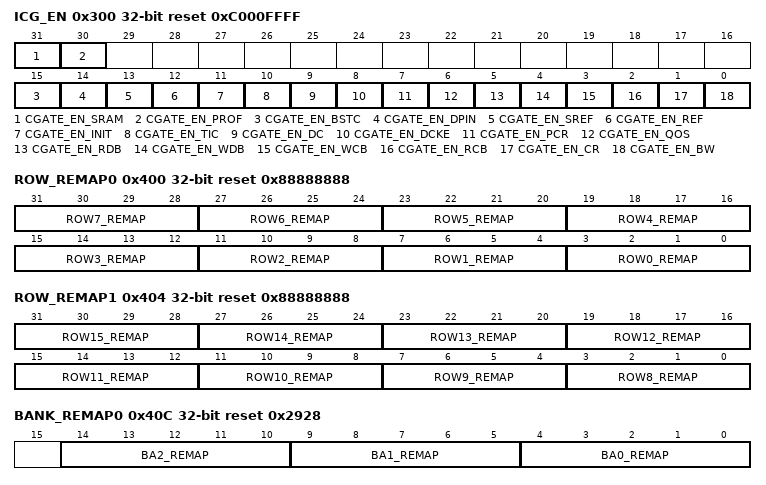
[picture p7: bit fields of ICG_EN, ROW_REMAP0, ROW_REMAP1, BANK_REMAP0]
0x300 ICG_EN reset 0xC000FFFF — Clock gating enable control register
  [31] CGATE_EN_SRAM — frontend & backend SRAM clock gating enable (except BSTC)
  [30] CGATE_EN_PROF — chx_dc_prof_event clock gating enable
  [15] CGATE_EN_BSTC — bstc module clock gating enable
  [14] CGATE_EN_DPIN — dpin module clock gating enable
  [13] CGATE_EN_SREF — self_ref module clock gating enable
  [12] CGATE_EN_REF — ref_unit module clock gating enable
  [11] CGATE_EN_INIT — init_unit module clock gating enable
  [10] CGATE_EN_TIC — tic module clock gating enable
  [9] CGATE_EN_DC — data_channel module clock gating enable
  [8] CGATE_EN_DCKE — cmd_sch, cmd_dispatch_block module clock gating enable
  [7] CGATE_EN_PCR — protocal control register clock gating enable
  [6] CGATE_EN_QOS — cmd_qos module clock gating enable
  [5] CGATE_EN_RDB — rdata_buf module clock gating enable
  [4] CGATE_EN_WDB — wdata_buf module clock gating enable
  [3] CGATE_EN_WCB — wcmd_buf module clock gating enable
  [2] CGATE_EN_RCB — rcmd_buf module clock gating enable
  [1] CGATE_EN_CR — cr_reg module clock gating enable
  [0] CGATE_EN_BW — bus_wrap module clock gating enable
0x400 ROW_REMAP0 reset 0x88888888 — DRAM row address remap control register 0, remap row address bit 0 ~ bit 7
  [4n+3:4n] ROW{n}_REMAP (n=0..7) — BFO = {n+5}, mapping to BUS_ADDR_BIT = BFO+ROW{n}_REMAP +log2(dq/8), if unused mapping to 0
0x404 ROW_REMAP1 reset 0x88888888 — DRAM row address remap control register 1, remap row address bit 8 ~ bit 15
  [4n-29:4n-32] ROW{n}_REMAP (n=8..15) — BFO = {n+5}, mapping to BUS_ADDR_BIT = BFO+ROW{n}_REMAP +log2(dq/8), if unused mapping to 0
0x408 ROW_REMAP2 reset 0x8 — DRAM row address remap control register 2, remap row address bit 16
  [3:0] ROW16_REMAP — BFO = 21, mapping to BUS_ADDR_BIT = BFO+ROW16_REMAP +log2(dq/8), if unused mapping to 0
0x40C BANK_REMAP0 reset 0x2928 — DRAM bank address remap control register 0, remap bank address bit 0 ~ bit 2
  [14:10] BA2_REMAP — BFO = 2, mapping to BUS_ADDR_BIT = BFO+BA2_REMAP +log2(dq/8), if unused mapping to 0
  [9:5] BA1_REMAP — BFO = 2, mapping to BUS_ADDR_BIT = BFO+BA1_REMAP +log2(dq/8), if unused mapping to 0
  [4:0] BA0_REMAP — BFO = 2, mapping to BUS_ADDR_BIT = BFO+BA0_REMAP +log2(dq/8), if unused mapping to 0
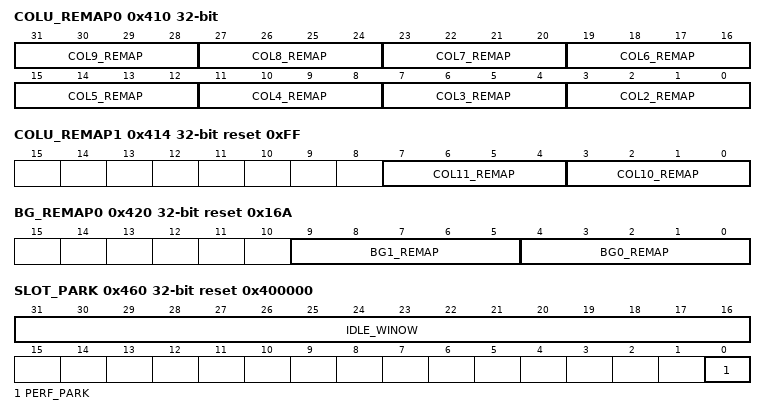
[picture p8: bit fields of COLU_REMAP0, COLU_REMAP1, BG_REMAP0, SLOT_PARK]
0x410 COLU_REMAP0 — DRAM clouaddress remap control register 0, remap clouaddress bit 2 ~bit 9
  [4n-5:4n-8] COL{n}_REMAP (n=2..9) — BFO = {n}, mapping to BUS_ADDR_BIT = BFO+COL{n}_REMAP +log2(dq/8), if unused mapping to 0
0x414 COLU_REMAP1 reset 0xFF — DRAM clouaddress remap control register 1, remap clouaddress bit 10
  [7:4] COL11_REMAP — BFO = 11, mapping to BUS_ADDR_BIT = BFO+COL11_REMAP +log2(dq/8), if unused mapping to 0 colu11_remap used for LPDDR3, column max to 12 bits
  [3:0] COL10_REMAP — BFO = 10, mapping to BUS_ADDR_BIT = BFO+COL10_REMAP +log2(dq/8), if unused mapping to 0 colu10_remap used for LPDDR3, column max to 11 bits
0x418 RANK_REMAP0 reset 0xB — DRAM rank address remap control register 0, remap rank address bit 0
  [4:0] RA_REMAP — BFO = 2, mapping to BUS_ADDR_BIT = BFO+RA_REMAP +log2(dq/8), if unused mapping to 0
0x41C CH_REMAP0 reset 0x19 — DRAM channel address remap control register 0, remap channel address bit 0
  [4:0] CH_REMAP — BFO = 2, mapping to BUS_ADDR_BIT = BFO+CH_REMAP +log2(dq/8), if unused mapping to 0
0x420 BG_REMAP0 reset 0x16A — DRAM bgaddress remap control register 0, remap bgaddress bit 0 ~bit1
  [9:5] BG1_REMAP — BFO = 2, mapping to BUS_ADDR_BIT = BFO+BG1_REMAP+log2(dq/8), if unused mapping to 0
  [4:0] BG0_REMAP — BFO = 2, mapping to BUS_ADDR_BIT = BFO+BG0_REMAP+log2(dq/8), if unused mapping to 0
0x424 ADDR_REMAP_CTRL — NONBINARY dram density: 3/6/12/24Gb
  [2:0] NONB_DSIZE — For LPDDR2/3 non-binary dram density (3/6/12/24Gb), only half of the row address space is valid. When the row[MSB]=1, the row[MSB-1] must be LOW. But now DRAM_SIZE(0x230) is used to set the max density. DRAM_SIZE can be non-binary size. So ADDR_REMAP_CTRL (0x424) would be not necessary for non-binary dram density. If physical address > dram_size, it is illegal DRAM access, frontend will block this cmd not send to backend, and send ERROR response. Also frontend interrupt will asserted for this illegal access. 3'd0: Not support non-binary dram density 3'd1: No dram density present at address with row[13]=row[12]=1 3'd2: No dram density present at address with row[14]=row[13]=1 3'd3: No dram density present at address with row[15]=row[14]=1 3'd4: No dram density present at address with row[16]=row[15]=1 3'd5~3'd7: Reserverd
0x460 SLOT_PARK reset 0x400000 — Slot parking control register
  [31:16] IDLE_WINOW — If current slot is no commands and current slot is not perfer parking slot, to wait IDLE_WINDOW cyclesand turn aroundslot if current slot is still no commands.
  [0] PERF_PARK — 0: Read slot 1: Write slot
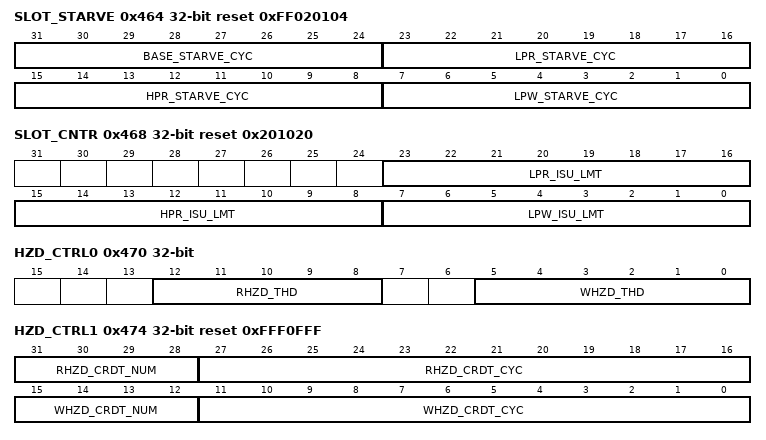
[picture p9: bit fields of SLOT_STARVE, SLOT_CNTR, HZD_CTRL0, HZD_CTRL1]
0x464 SLOT_STARVE reset 0xFF020104 — Slot starvation control register
  [31:24] BASE_STARVE_CYC — This is basic starvation counter cycles for LPR_STARVE_CYC, HPR_STARVE_CYC and LPW_STARVE_CYC
  [23:16] LPR_STARVE_CYC — The timeout of LPR slot would be set when LPR commans is no servicing in the interval time = (LPR_STARVE_CYC*BASE_STARVE_CYC)
  [15:8] HPR_STARVE_CYC — The timeout of HPR slot would be set when HPR commans is no servicing in the interval time = (HPR_STARVE_CYC*BASE_STARVE_CYC)
  [7:0] LPW_STARVE_CYC — The timeout of LPW slot would be set when HPR commans is no servicing in the interval time = (LPW_STARVE_CYC*BASE_STARVE_CYC)
0x468 SLOT_CNTR reset 0x201020 — Slot constrain register
  [23:16] LPR_ISU_LMT — This is limited number to issue LPR commands when LPR slot is at urgent state.
  [15:8] HPR_ISU_LMT — This is limited number to issue HPR commands when HPR slot is at urgent state.
  [7:0] LPW_ISU_LMT — This is limited number to issue LPW commands when LPW slot is at urgent state.
0x46C EXP_CTRL reset 0x1 — Expire control register
  [7:0] EXP_BASE — Used for expire function, exp_base value count down to 1, global_exp_timer+1
0x470 HZD_CTRL0 — Hazard priority control register 0
  [12:8] RHZD_THD — Used to constrain read hazard priority. When RHZD_THD setting and read command number >= RHZD_THD, it would keep the original read hazard priority at command QoS. If the value of RHZD_THD is 0, it would disable this hazard constrain function.
  [5:0] WHZD_THD — Used to constrain write hazard priority. When WHZD_THD setting and write command number >= WHZD_THD, it would keep the original write hazard priority at command QoS. If the value of WHZD_THD is 0, it would disable this hazard constrain function.
0x474 HZD_CTRL1 reset 0xFFF0FFF — Hazard priority control register 0
  [31:28] RHZD_CRDT_NUM — This is the max. number to limit the read hazard credit number. When read hazard credit number is larger then 0, it would keep the original read hazard priority at command QoS. If RHZD_CRDT_NUM is 0, it would disable this hazard constrain function.
  [27:16] RHZD_CRDT_CYC — Read hazard credit number would added 1 to in every interval cycles (RHZD_CRDT_CYC).
  [15:12] WHZD_CRDT_NUM — This is the max. number to limit the write hazard credit number. When write hazard credit number is larger then 0, it would keep the original write hazard priority at command QoS. If WHZD_CRDT_NUM is 0, it would disable this hazard constrain function.
  [11:0] WHZD_CRDT_CYC — Write hazard credit number would add 1 to in every interval cycles (WHZD_CRDT_CYC).
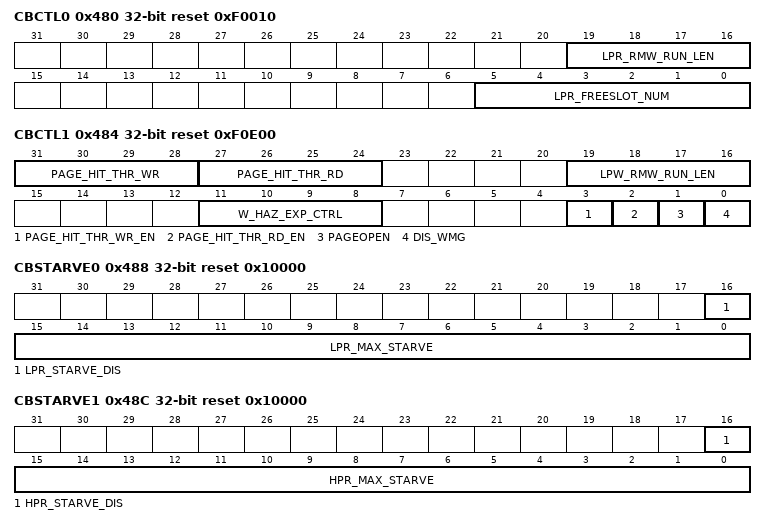
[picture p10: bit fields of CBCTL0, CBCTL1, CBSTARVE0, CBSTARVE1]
0x480 CBCTL0 reset 0xF0010 — Command buffer control register 0
  [19:16] LPR_RMW_RUN_LEN — When CBSTARVE3.LPR_RMW_MAX_STARVEreaches,lpr_rmwcmd que's priority will increase higher thanthe LPR inputexpired cmd and be serviced continuously LPR_RMW_RUN_LENlpr_rmw cmd when lpr_rmw cmd que's is not empty.
  [5:0] LPR_FREESLOT_NUM — Number of Free-slot for LP reads is the value +1; Due to HP reads share w/ LP reads in the Read Command Buffer, the number of Free-slot for HP reads is the value : 32 - (LPR_FREESLOT_NUM + 1)
0x484 CBCTL1 reset 0xF0E00 — Command buffer control register 1
  [31:28] PAGE_HIT_THR_WR — When PAGE_HIT_THR_WR_EN=1, the cmd_buf for write same bank page_hit cmd threshold value is PAGE_HIT_THR_WR.
  [27:24] PAGE_HIT_THR_RD — When PAGE_HIT_THR_RD_EN=1, the cmd_buf for read same bank page_hit cmd threshold value is PAGE_HIT_THR_RD
  [19:16] LPW_RMW_RUN_LEN — When CBSTARVE4.LPW_RMW_MAX_STARVE reaches, lpw_rmw re-insert cmd priority will increase higher thanthe LPW inputexpired cmd & expired re-insert and be serviced continuously LPW_RMW_RUN_LENlpw_rmw cmd when lpr_rmw re-insert cmd is valid.
  [11:8] W_HAZ_EXP_CTRL — For RAW/WAW hit wcmd_entry triggers expired function to speed up hazard handler. W_HAZ_EXP_CTRL[1:0] 2'b11: always enable 2'b10: urgent only for read/write urgent signal assert 2'b0x: disable When W_HAZ_EXP_CTRL[3:2] 2'b1x: RAW hazard 2'bx1: WAW hazard 2'b00: disable Default function is urgent only.
  [3] PAGE_HIT_THR_WR_EN — when PAGE_HIT_THR_RD_EN=1, the cmd_buf for write same bank page_hit cmd threshold value is PAGE_HIT_THR_WR
  [2] PAGE_HIT_THR_RD_EN — when PAGE_HIT_THR_RD_EN=1, the cmd_buf for read same bank page_hit cmd threshold value is PAGE_HIT_THR_RD
  [1] PAGEOPEN — When PAGEOPEN =1,the last cmd of each bank will not be issued with auto-precharge to PCTL.
  [0] DIS_WMG — Write merge function disable, it only works when enable WMG_EN feature.
0x488 CBSTARVE0 reset 0x10000 — command buffer starve register 0
  [16] LPR_STARVE_DIS — 0x1: Disable
  [15:0] LPR_MAX_STARVE — LPR entry of command buffer is not serviced before it goes to expired in the interval time= {LPR_MAX_STARVE, timestamp_cycle}
0x48C CBSTARVE1 reset 0x10000 — command buffer starve register 1
  [16] HPR_STARVE_DIS — 0x1: Disable
  [15:0] HPR_MAX_STARVE — HPR entry of command buffer is not serviced before it goes to expired in the interval time= {HPR_MAX_STARVE, timestamp_cycle}
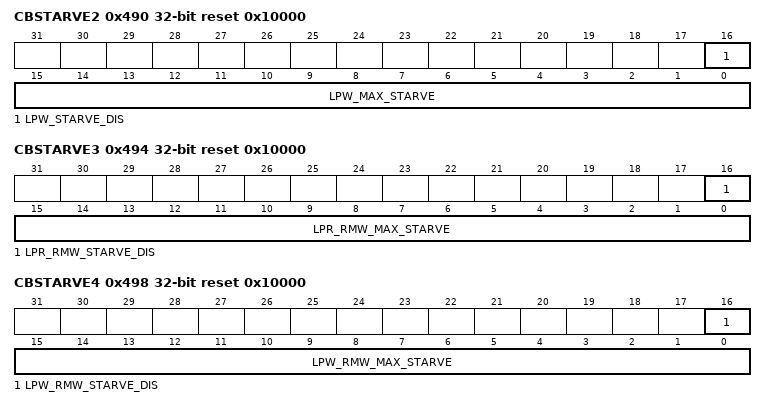
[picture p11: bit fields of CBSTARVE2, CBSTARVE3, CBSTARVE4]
0x490 CBSTARVE2 reset 0x10000 — command buffer starve register 2
  [16] LPW_STARVE_DIS — 0x1: Disable
  [15:0] LPW_MAX_STARVE — LPW entry of command buffer is not serviced before it goes to expired in the interval time= {LPW_MAX_STARVE, timestamp_cycle}
0x494 CBSTARVE3 reset 0x10000 — command buffer starve register 3
  [16] LPR_RMW_STARVE_DIS — 0x1: Disable
  [15:0] LPR_RMW_MAX_STARVE — lpr_rmw cmd que of command buffer is not serviced before it goes to expired in the interval time= {LPR_RMW_MAX_STARVE, timestamp_cycle}
0x498 CBSTARVE4 reset 0x10000 — command buffer starve register 4
  [16] LPW_RMW_STARVE_DIS — 0x1: Disable
  [15:0] LPW_RMW_MAX_STARVE — lpw_rmw re-insert cmd of command buffer is not serviced before it goes to expired in the interval time= {LPW_RMW_MAX_STARVE, timestamp_cycle}
0x4A0 BSCH — number of times for command schedule keeps to select the same bank
  [3:0] BA_SEL_LMT — Number of times for command schedule keeps to select the same bank
